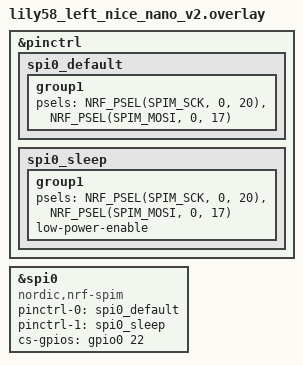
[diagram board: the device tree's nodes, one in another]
/*
 * Lily58 Pro - Native Nice!View Support
 * The Lily58 Pro has a 5-pin header pre-wired for Nice!View
 */

&pinctrl {
    spi0_default: spi0_default {
        group1 {
            psels = <NRF_PSEL(SPIM_SCK, 0, 20)>,
                <NRF_PSEL(SPIM_MOSI, 0, 17)>;
        };
    };
    spi0_sleep: spi0_sleep {
        group1 {
            psels = <NRF_PSEL(SPIM_SCK, 0, 20)>,
                <NRF_PSEL(SPIM_MOSI, 0, 17)>;
            low-power-enable;
        };
    };
};

// Define SPI bus for Nice!View (Lily58 Pro native wiring)
nice_view_spi: &spi0 {
    compatible = "nordic,nrf-spim";
    status = "okay";
    pinctrl-0 = <&spi0_default>;
    pinctrl-1 = <&spi0_sleep>;
    pinctrl-names = "default", "sleep";
    cs-gpios = <&gpio0 22 GPIO_ACTIVE_HIGH>;  // P0.22 (D4) CS pin - Lily58 Pro actual wiring
};

